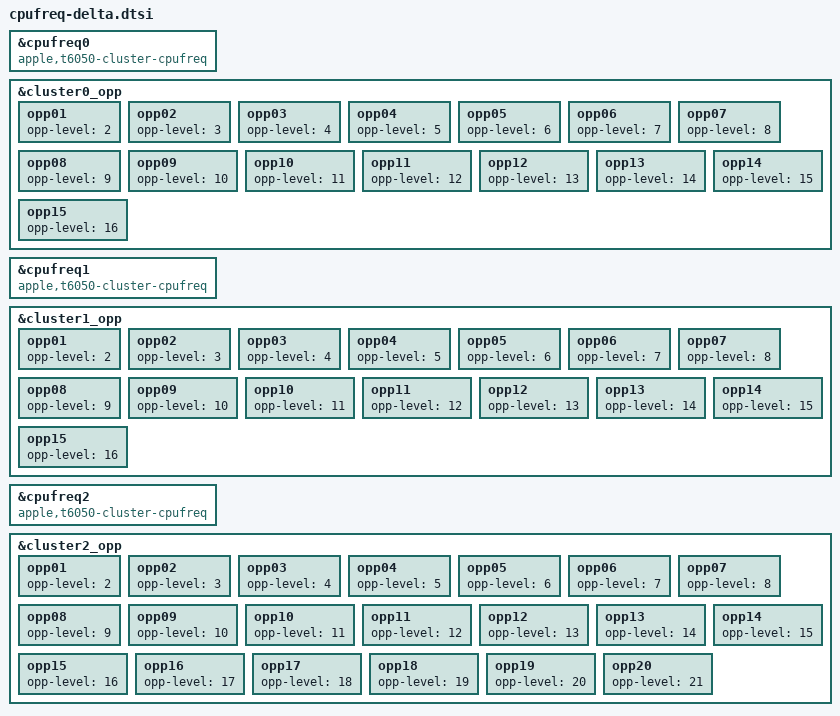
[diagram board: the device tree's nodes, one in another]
// SPDX-License-Identifier: GPL-2.0+ OR MIT
/*
 * CPU frequency scaling delta for t6050 / J716c: DRAFT, generated by
 * kernel/experiments/cpufreq-t6050/make_cpufreq_dt.py from a shipped Stage-B DT and
 * hardware/adt/adt-sanitized.json.  Not booted.  Each controller below loses
 * status = "disabled"; each OPP entry gets opp-level = row + 2 (macOS writes
 * DESIRED1 = 2 + row; native state-to-frequency mapping remains unverified).
 */

&cpufreq0 {	/* /soc/performance-controller@210e20000 */
	/delete-property/ status;
	compatible = "apple,t6050-cluster-cpufreq";
};

&cluster0_opp {	/* /opp-table-0 */
	opp01 { opp-level = <2>; };	/* was <1>; 1344 MHz */
	opp02 { opp-level = <3>; };	/* was <2>; 1644 MHz */
	opp03 { opp-level = <4>; };	/* was <3>; 1992 MHz */
	opp04 { opp-level = <5>; };	/* was <4>; 2304 MHz */
	opp05 { opp-level = <6>; };	/* was <5>; 2652 MHz */
	opp06 { opp-level = <7>; };	/* was <6>; 2964 MHz */
	opp07 { opp-level = <8>; };	/* was <7>; 3240 MHz */
	opp08 { opp-level = <9>; };	/* was <8>; 3504 MHz */
	opp09 { opp-level = <10>; };	/* was <9>; 3696 MHz */
	opp10 { opp-level = <11>; };	/* was <10>; 3876 MHz */
	opp11 { opp-level = <12>; };	/* was <11>; 4044 MHz */
	opp12 { opp-level = <13>; };	/* was <12>; 4176 MHz */
	opp13 { opp-level = <14>; };	/* was <13>; 4284 MHz */
	opp14 { opp-level = <15>; };	/* was <14>; 4308 MHz */
	opp15 { opp-level = <16>; };	/* was <15>; 4380 MHz */
};

&cpufreq1 {	/* /soc/performance-controller@211e20000 */
	/delete-property/ status;
	compatible = "apple,t6050-cluster-cpufreq";
};

&cluster1_opp {	/* /opp-table-1 */
	opp01 { opp-level = <2>; };	/* was <1>; 1344 MHz */
	opp02 { opp-level = <3>; };	/* was <2>; 1644 MHz */
	opp03 { opp-level = <4>; };	/* was <3>; 1992 MHz */
	opp04 { opp-level = <5>; };	/* was <4>; 2304 MHz */
	opp05 { opp-level = <6>; };	/* was <5>; 2652 MHz */
	opp06 { opp-level = <7>; };	/* was <6>; 2964 MHz */
	opp07 { opp-level = <8>; };	/* was <7>; 3240 MHz */
	opp08 { opp-level = <9>; };	/* was <8>; 3504 MHz */
	opp09 { opp-level = <10>; };	/* was <9>; 3696 MHz */
	opp10 { opp-level = <11>; };	/* was <10>; 3876 MHz */
	opp11 { opp-level = <12>; };	/* was <11>; 4044 MHz */
	opp12 { opp-level = <13>; };	/* was <12>; 4176 MHz */
	opp13 { opp-level = <14>; };	/* was <13>; 4284 MHz */
	opp14 { opp-level = <15>; };	/* was <14>; 4308 MHz */
	opp15 { opp-level = <16>; };	/* was <15>; 4380 MHz */
};

&cpufreq2 {	/* /soc/performance-controller@212e20000 */
	/delete-property/ status;
	compatible = "apple,t6050-cluster-cpufreq";
};

&cluster2_opp {	/* /opp-table-2 */
	opp01 { opp-level = <2>; };	/* was <1>; 1308 MHz */
	opp02 { opp-level = <3>; };	/* was <2>; 1620 MHz */
	opp03 { opp-level = <4>; };	/* was <3>; 1980 MHz */
	opp04 { opp-level = <5>; };	/* was <4>; 2292 MHz */
	opp05 { opp-level = <6>; };	/* was <5>; 2580 MHz */
	opp06 { opp-level = <7>; };	/* was <6>; 2880 MHz */
	opp07 { opp-level = <8>; };	/* was <7>; 3180 MHz */
	opp08 { opp-level = <9>; };	/* was <8>; 3432 MHz */
	opp09 { opp-level = <10>; };	/* was <9>; 3648 MHz */
	opp10 { opp-level = <11>; };	/* was <10>; 3828 MHz */
	opp11 { opp-level = <12>; };	/* was <11>; 3984 MHz */
	opp12 { opp-level = <13>; };	/* was <12>; 4104 MHz */
	opp13 { opp-level = <14>; };	/* was <13>; 4188 MHz */
	opp14 { opp-level = <15>; };	/* was <14>; 4236 MHz */
	opp15 { opp-level = <16>; };	/* was <15>; 4284 MHz */
	opp16 { opp-level = <17>; };	/* was <16>; 4308 MHz */
	opp17 { opp-level = <18>; };	/* was <17>; 4332 MHz */
	opp18 { opp-level = <19>; };	/* was <18>; 4428 MHz */
	opp19 { opp-level = <20>; };	/* was <19>; 4512 MHz */
	opp20 { opp-level = <21>; };	/* was <20>; 4608 MHz */
};
